# SN32F240B register map
Vendor: SONiX Technology Co., Ltd.; Series: SN32F240B; File version: 1.1
CPU: CM0 r0p0, little endian, no MPU, no FPU, 2 interrupt priority bits
Registers are 32-bit, read-write, reset 0x0 unless marked. A register's access mark holds for its fields unless they carry their own. Offsets are from the block's base; [hi:lo] are bit positions; {n}, {i} and the like mark numbered series.

## SN_ADC — ADC
Base 0x40026000
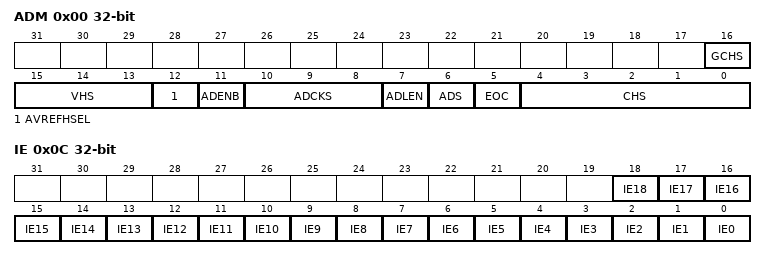
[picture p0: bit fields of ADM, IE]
0x00 ADM — Offset:0x00 ADC Management Register
  [16] GCHS — ADC global channel enable
    0=Disable AIN channel; 1=Enable AIN channel
  [15:13] VHS — Internal Ref. voltage source
    0=000b (Internal 2.0V as ADC internal reference high voltage); 1=001b (Internal 3.0V as ADC internal reference high voltage); 2=010b (Internal 4.5V as ADC internal reference high voltage); 4=100b (VDD as ADC internal reference high voltage, Internal 2.0V as AIN10); 5=101b (VDD as ADC internal reference high voltage, Internal 3.0V as AIN10); 6=110b (VDD as ADC internal reference high voltage, Internal 4.5V as AIN10); 7=111b (VDD as ADC internal reference high voltage)
  [12] AVREFHSEL — ADC high reference voltage source
    0=Interal VDD (P2.0 acts as GPIO or AIN0 pin); 1=External reference voltage (P2.0 acts as AVREFH pin)
  [11] ADENB — ADC enable
    0=Disable ADC; 1=Enable ADC
  [10:8] ADCKS — ADC clock source divider
    0=ADC_PCLK/1; 1=ADC_PCLK/2; 2=ADC_PCLK/4; 3=ADC_PCLK/8; 5=ADC_PCLK/16; 6=ADC_PCLK/32
  [7] ADLEN — ADC resolution
    0=8-bit ADB; 1=12-bit ADB
  [6] ADS — ADC start control
    0=Stop (ADC stopped); 1=Start ADC conversion
  [5] EOC — ADC status
    0=Busy (ADC processing); 1=End (End of conversion)
  [4:0] CHS — ADC input channel
    {v}=AIN{v} (v=0..15); 16=AIN16(Internal reference voltage 4.5V/3V/2V); 17=AIN17(VDD); 18=AIN18(VSS)
0x04 ADB ro (reset mask 0xFFF) — Offset:0x04 ADC Data Register
0x0C IE — Offset:0x0C ADC Interrupt Enable Register
  [n] IE{n} (n=0..18) — AIN{n} interrupt enable
    0=Disable AIN{n} interrupt; 1=Enable (ADC interrupt is triggered when AIN{n} completes ADC conversion)
0x10 RIS (reset mask 0x7FFFF) — Offset:0x10 ADC Raw Interrupt Status Register

## SN_CT16B0 — 16-bit Timer 0 with Capture function
Base 0x40000000
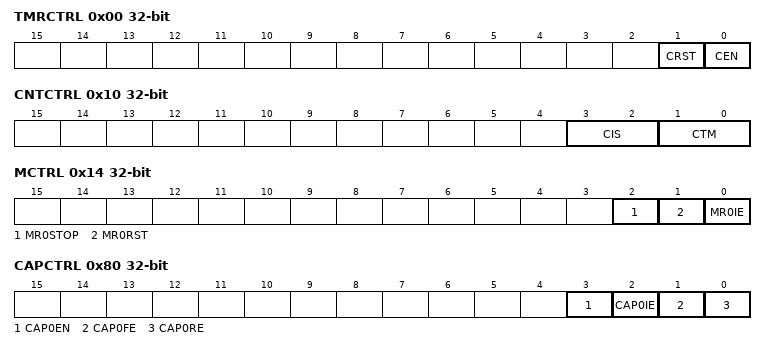
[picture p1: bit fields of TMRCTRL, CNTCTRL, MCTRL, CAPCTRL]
0x00 TMRCTRL — Offset:0x00 CT16Bn Timer Control Register
  [1] CRST — Counter Reset
    0=Disable; 1=Reset Counter (Timer Counter and the Prescale Counter are synchronously reset on the next positive edge of PCLK)
  [0] CEN — Counter enable
    0=Disable counter; 1=Enable Timer Counter and Prescale Counter for counting
0x04 TC — Offset:0x04 CT16Bn Timer Counter Register
  [15:0] TC — Timer Counter
0x08 PRE — Offset:0x08 CT16Bn Prescale Register
  [7:0] PRE — Prescaler
0x0C PC — Offset:0x0C CT16Bn Prescale Counter Register
  [7:0] PC — Prescaler Counter
0x10 CNTCTRL — Offset:0x10 CT16Bn Counter Control Register
  [3:2] CIS — Counter Input Select
    0=CT16Bn_CAP0
  [1:0] CTM — Counter/Timer Mode
    0=Timer Mode (Every rising PCLK edge); 1=Counter Mode (TC is incremented on rising edges on the CAP0 input selected by CIS bits.); 2=Counter Mode (TC is incremented on falling edges on the CAP0 input selected by CIS bits.); 3=Counter Mode (TC is incremented on both edges on the CAP0 input selected by CIS bits.)
0x14 MCTRL — Offset:0x14 CT16Bn Match Control Register
  [2] MR0STOP — Stop TC and PC and clear CEN bit when MR0 matches TC
    0=Disable; 1=Enable (Stop TC and PC and clear CEN bit when MR0 matches TC)
  [1] MR0RST — Enable reset TC when MR0 matches TC
    0=Disable; 1=Enable (Reset TC when MR0 matches TC)
  [0] MR0IE — Enable generating an interrupt when MR0 matches TC
    0=Disable; 1=Enable (Generating an interrupt when MR0 matches TC)
0x20 MR0 (reset mask 0xFFFF) — Offset:0x20 CT16Bn MR0 Register
0x80 CAPCTRL — Offset:0x80 CT16Bn Capture Control Register
  [3] CAP0EN — CAP0 function enable
    0=Disable; 1=Enable CAP0 function
  [2] CAP0IE — Interrupt on CT16Bn_CAP0 event
    0=Disable; 1=Enable (A CAP0 load due to a CT16Bn_CAP0 event will generate an interrupt.)
  [1] CAP0FE — Capture on CT16Bn_CAP0 falling edge
    0=Disable; 1=Enable (A sequence of 1 then 0 on CT16Bn_CAP0 will cause CAP0 to be loaded with the contents of TC.)
  [0] CAP0RE — Capture on CT16Bn_CAP0 rising edge
    0=Disable; 1=Enable (A sequence of 0 then 1 on CT16Bn_CAP0 will cause CAP0 to be loaded with the contents of TC.)
0x84 CAP0 ro — Offset:0x84 CT16Bn CAP0 Register
  [15:0] CAP0 — Timer counter capture value
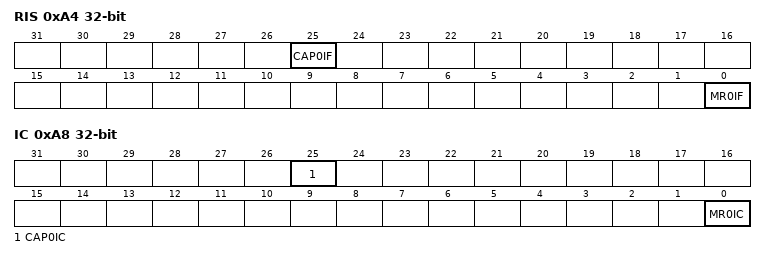
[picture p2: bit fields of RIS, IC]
0xA4 RIS ro — Offset:0xA4 CT16Bn Raw Interrupt Status Register
  [25] CAP0IF — Interrupt flag for capture channel 0
    0=No (No interrupt on CAP0); 1=Met interrupt requirements (Interrupt requirements met on CAP0)
  [0] MR0IF — Match channel 0 interrupt flag
    0=No interrupt on match channel 0; 1=Met interrupt requirements (Interrupt requirements met on match channel 0)
0xA8 IC wo — Offset:0xA8 CT16Bn Interrupt Clear Register
  [25] CAP0IC — CAP0IF clear bit
    0=No effect; 1=Clear CAP0IF
  [0] MR0IC — MR0IF clear bit
    0=No effect; 1=Clear MR0IF
